AUTOSAR XML (schema 00049)
package /FlexECUDemoApplicationSoftware
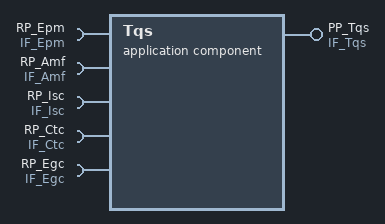
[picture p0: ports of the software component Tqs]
  application sw component type Tqs
    provide port PP_Tqs: provided-interface=IF_Tqs
    5 x require port:
      RP_Epm: required-interface=IF_Epm
      RP_Amf: required-interface=IF_Amf
      RP_Isc: required-interface=IF_Isc
      RP_Ctc: required-interface=IF_Ctc
      RP_Egc: required-interface=IF_Egc
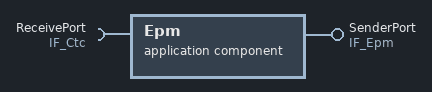
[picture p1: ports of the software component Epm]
  application sw component type Epm
    provide port SenderPort: provided-interface=IF_Epm
    require port ReceivePort: required-interface=IF_Ctc
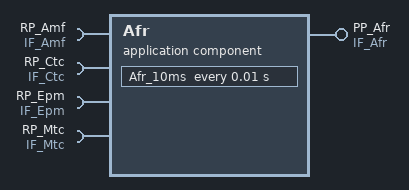
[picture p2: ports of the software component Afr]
  application sw component type Afr
    4 x require port:
      RP_Amf: required-interface=IF_Amf
      RP_Ctc: required-interface=IF_Ctc
      RP_Epm: required-interface=IF_Epm
      RP_Mtc: required-interface=IF_Mtc
    provide port PP_Afr: provided-interface=IF_Afr
    behavior IB_Afr
      timing event TE_10ms: start-on-event=Afr_10ms, period=0.01
      runnable Afr_10ms
        data-read-access:
          access DRA_Afr
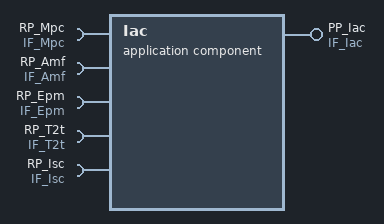
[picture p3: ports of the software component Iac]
  application sw component type Iac
    provide port PP_Iac: provided-interface=IF_Iac
    5 x require port:
      RP_Mpc: required-interface=IF_Mpc
      RP_Amf: required-interface=IF_Amf
      RP_Epm: required-interface=IF_Epm
      RP_T2t: required-interface=IF_T2t
      RP_Isc: required-interface=IF_Isc
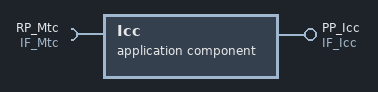
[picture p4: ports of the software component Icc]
  application sw component type Icc
    provide port PP_Icc: provided-interface=IF_Icc
    require port RP_Mtc: required-interface=IF_Mtc
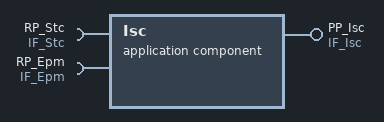
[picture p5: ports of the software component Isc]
  application sw component type Isc
    provide port PP_Isc: provided-interface=IF_Isc
    require port RP_Stc: required-interface=IF_Stc
    require port RP_Epm: required-interface=IF_Epm
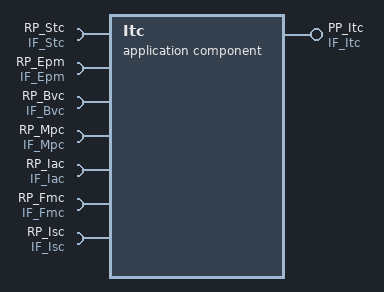
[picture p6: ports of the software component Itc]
  application sw component type Itc
    provide port PP_Itc: provided-interface=IF_Itc
    7 x require port:
      RP_Stc: required-interface=IF_Stc
      RP_Epm: required-interface=IF_Epm
      RP_Bvc: required-interface=IF_Bvc
      RP_Mpc: required-interface=IF_Mpc
      RP_Iac: required-interface=IF_Iac
      RP_Fmc: required-interface=IF_Fmc
      RP_Isc: required-interface=IF_Isc
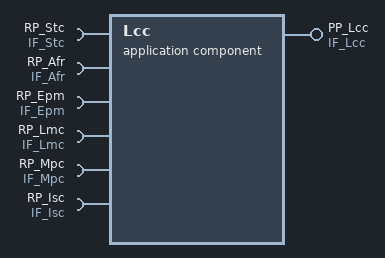
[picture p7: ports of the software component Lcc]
  application sw component type Lcc
    provide port PP_Lcc: provided-interface=IF_Lcc
    6 x require port:
      RP_Stc: required-interface=IF_Stc
      RP_Afr: required-interface=IF_Afr
      RP_Epm: required-interface=IF_Epm
      RP_Lmc: required-interface=IF_Lmc
      RP_Mpc: required-interface=IF_Mpc
      RP_Isc: required-interface=IF_Isc
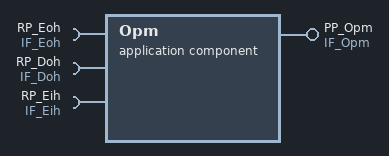
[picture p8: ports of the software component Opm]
  application sw component type Opm
    provide port PP_Opm: provided-interface=IF_Opm
    require port RP_Eoh: required-interface=IF_Eoh
    require port RP_Doh: required-interface=IF_Doh
    require port RP_Eih: required-interface=IF_Eih
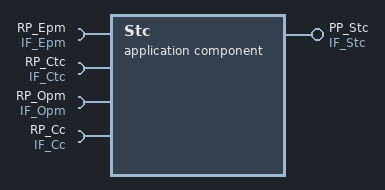
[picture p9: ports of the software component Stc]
  application sw component type Stc
    provide port PP_Stc: provided-interface=IF_Stc
    4 x require port:
      RP_Epm: required-interface=IF_Epm
      RP_Ctc: required-interface=IF_Ctc
      RP_Opm: required-interface=IF_Opm
      RP_Cc: required-interface=IF_Cc
  application sw component type Fmc
    6 x require port:
      RP_Tqs: required-interface=IF_Tqs
      RP_Amf: required-interface=IF_Amf
      RP_Afr: required-interface=IF_Afr
      RP_Epm: required-interface=IF_Epm
      RP_Itc: required-interface=IF_Itc
      RP_Lcc: required-interface=IF_Lcc
    provide port PP_Fmc: provided-interface=IF_Fmc
  application sw component type Amf
    provide port PP_Amf: provided-interface=IF_Amf
    5 x require port:
      RP_Ctc: required-interface=IF_Ctc
      RP_Epm: required-interface=IF_Epm
      RP_Mpc: required-interface=IF_Mpc
      RP_Amc: required-interface=IF_Amc
      RP_Mtc: required-interface=IF_Mtc
  application sw component type T2t
    provide port PP_T2t: provided-interface=IF_T2t
    7 x require port:
      RP_Tqs: required-interface=IF_Tqs
      RP_Mpc: required-interface=IF_Mpc
      RP_Isc: required-interface=IF_Isc
      RP_Epm: required-interface=IF_Epm
      RP_Stc: required-interface=IF_Stc
      RP_Afr: required-interface=IF_Afr
      RP_Iac: required-interface=IF_Iac
  application sw component type Cc
    provide port PP_Cc: provided-interface=IF_Cc
    5 x require port:
      RP_T2t: required-interface=IF_T2t
      RP_Epm: required-interface=IF_Epm
      RP_Egc: required-interface=IF_Egc
      RP_Kl50: required-interface=IF_Kl50
      RP_Icc: required-interface=IF_Icc
